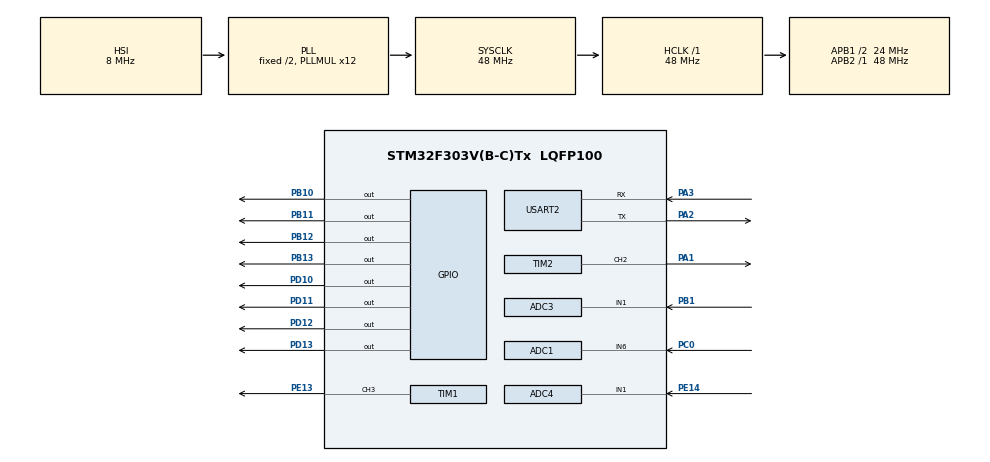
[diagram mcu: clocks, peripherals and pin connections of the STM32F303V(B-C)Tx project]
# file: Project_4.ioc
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ADC1.Channel-1\#ChannelRegularConversion=ADC_CHANNEL_6
ADC1.NbrOfConversionFlag=1
ADC1.Offset-1\#ChannelRegularConversion=0
ADC1.OffsetNumber-1\#ChannelRegularConversion=ADC_OFFSET_NONE
ADC1.Rank-1\#ChannelRegularConversion=1
ADC1.SamplingTime-1\#ChannelRegularConversion=ADC_SAMPLETIME_601CYCLES_5
ADC1.SamplingTimeOPAMP-1\#ChannelRegularConversion=ADC_SAMPLETIME_19CYCLES_5
ADC1.master=1
ADC3.Channel-0\#ChannelRegularConversion=ADC_CHANNEL_1
ADC3.NbrOfConversionFlag=1
ADC3.Offset-0\#ChannelRegularConversion=0
ADC3.OffsetNumber-0\#ChannelRegularConversion=ADC_OFFSET_NONE
ADC3.Rank-0\#ChannelRegularConversion=1
ADC3.SamplingTime-0\#ChannelRegularConversion=ADC_SAMPLETIME_601CYCLES_5
ADC3.SamplingTimeOPAMP-0\#ChannelRegularConversion=ADC_SAMPLETIME_19CYCLES_5
ADC3.master=1
ADC4.Channel-1\#ChannelRegularConversion=ADC_CHANNEL_1
ADC4.NbrOfConversionFlag=1
ADC4.Offset-1\#ChannelRegularConversion=0
ADC4.OffsetNumber-1\#ChannelRegularConversion=ADC_OFFSET_NONE
ADC4.Rank-1\#ChannelRegularConversion=1
ADC4.SamplingTime-1\#ChannelRegularConversion=ADC_SAMPLETIME_601CYCLES_5
Mcu.Family=STM32F3
Mcu.Name=STM32F303V(B-C)Tx
Mcu.Package=LQFP100
NVIC.ADC1_2_IRQn=true\:0\:0\:true\:false\:true\:true\:true
NVIC.ADC3_IRQn=true\:0\:0\:true\:false\:true\:true\:true
NVIC.ADC4_IRQn=true\:0\:0\:true\:false\:true\:true\:true
NVIC.PriorityGroup=NVIC_PRIORITYGROUP_4
NVIC.TIM3_IRQn=true\:0\:0\:true\:false\:true\:true\:true
NVIC.TIM4_IRQn=true\:0\:0\:true\:false\:true\:true\:true
NVIC.TIM6_DAC_IRQn=true\:0\:0\:true\:false\:true\:true\:true
NVIC.USART2_IRQn=true\:0\:0\:true\:false\:true\:true\:true
PA1.Signal=S_TIM2_CH2
PA2.Mode=Asynchronous
PA2.Signal=USART2_TX
PA3.Mode=Asynchronous
PA3.Signal=USART2_RX
PB1.Mode=IN1-Single-Ended
PB1.Signal=ADC3_IN1
PB10.Signal=GPIO_Output
PB11.Signal=GPIO_Output
PB12.Signal=GPIO_Output
PB13.Signal=GPIO_Output
PC0.Signal=ADCx_IN6
PD10.Signal=GPIO_Output
PD11.Signal=GPIO_Output
PD12.Signal=GPIO_Output
PD13.Signal=GPIO_Output
PE13.Signal=S_TIM1_CH3
PE14.Mode=IN1-Single-Ended
PE14.Signal=ADC4_IN1
ProjectManager.HeapSize=0x200
ProjectManager.StackSize=0x400
ProjectManager.TargetToolchain=STM32CubeIDE
RCC.AHBFreq_Value=48000000
RCC.APB1CLKDivider=RCC_HCLK_DIV2
RCC.APB1Freq_Value=24000000
RCC.APB1TimFreq_Value=48000000
RCC.APB2Freq_Value=48000000
RCC.APB2TimFreq_Value=48000000
RCC.CortexFreq_Value=48000000
RCC.HCLKFreq_Value=48000000
RCC.HSE_VALUE=8000000
RCC.HSI_VALUE=8000000
RCC.LSE_VALUE=32768
RCC.PLLMUL=RCC_PLL_MUL12
RCC.SYSCLKFreq_VALUE=48000000
RCC.SYSCLKSourceVirtual=RCC_SYSCLKSOURCE_PLLCLK
RCC.USBFreq_Value=48000000
SH.ADCx_IN6.0=ADC1_IN6,IN6-Single-Ended
SH.S_TIM1_CH3.0=TIM1_CH3,PWM Generation3 CH3
SH.S_TIM2_CH2.0=TIM2_CH2,PWM Generation2 CH2
TIM1.Channel-PWM\ Generation3\ CH3=TIM_CHANNEL_3
TIM1.Period=9
TIM1.Prescaler=9
TIM2.Channel-PWM\ Generation2\ CH2=TIM_CHANNEL_2
TIM3.Period=9999
TIM3.Prescaler=47
TIM4.Period=999
TIM4.Prescaler=191
TIM6.Period=9999
TIM6.Prescaler=239
USART2.VirtualMode-Asynchronous=VM_ASYNC
VP_TIM1_VS_ClockSourceINT.Mode=Internal
VP_TIM2_VS_ClockSourceINT.Mode=Internal
VP_TIM3_VS_ClockSourceINT.Mode=Internal
VP_TIM4_VS_ClockSourceINT.Mode=Internal
VP_TIM6_VS_ClockSourceINT.Mode=Enable_Timer
board=custom

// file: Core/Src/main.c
/* USER CODE BEGIN Header */
/**
  ******************************************************************************
  * @file           : main.c
  * @brief          : Main program body
  ******************************************************************************
  * @attention
  *
  * <h2><center>&copy; Copyright (c) 2022 STMicroelectronics.
  * All rights reserved.</center></h2>
  *
  * This software component is licensed by ST under BSD 3-Clause license,
  * the "License"; You may not use this file except in compliance with the
  * License. You may obtain a copy of the License at:
  *                        opensource.org/licenses/BSD-3-Clause
  *
  ******************************************************************************
  */
/* USER CODE END Header */
#include "main.h"

ADC_HandleTypeDef hadc1;
ADC_HandleTypeDef hadc3;
ADC_HandleTypeDef hadc4;

TIM_HandleTypeDef htim1;
TIM_HandleTypeDef htim2;
TIM_HandleTypeDef htim3;
TIM_HandleTypeDef htim4;
TIM_HandleTypeDef htim6;

UART_HandleTypeDef huart2;

void SystemClock_Config(void);

static void MX_GPIO_Init(void);

static void MX_USART2_UART_Init(void);

static void MX_ADC4_Init(void);

static void MX_ADC1_Init(void);

static void MX_TIM1_Init(void);

static void MX_TIM2_Init(void);

static void MX_TIM3_Init(void);

static void MX_ADC3_Init(void);

static void MX_TIM4_Init(void);

static void MX_TIM6_Init(void);

/* USER CODE BEGIN 0 */
TIM_HandleTypeDef *pwm_timer = &htim2;
uint32_t pwm_channel = TIM_CHANNEL_2;

void PWM_Start() {
    HAL_TIM_PWM_Start(pwm_timer, pwm_channel);
}
/* USER CODE END 0 */

int main(void) {

    /* MCU Configuration--------------------------------------------------------*/

    /* Reset of all peripherals, Initializes the Flash interface and the Systick. */
    HAL_Init();

    /* Configure the system clock */
    SystemClock_Config();

    /* Initialize all configured peripherals */
    MX_GPIO_Init();
    MX_USART2_UART_Init();
    MX_ADC4_Init();
    MX_ADC1_Init();
    MX_TIM1_Init();
    MX_TIM2_Init();
    MX_TIM3_Init();
    MX_ADC3_Init();
    MX_TIM4_Init();
    MX_TIM6_Init();
    /* USER CODE BEGIN 2 */
    HAL_ADC_Start_IT(&hadc1);
    HAL_ADC_Start_IT(&hadc3);
    HAL_ADC_Start_IT(&hadc4);

    HAL_TIM_PWM_Start(&htim1, TIM_CHANNEL_3);

    PWM_Start();

    HAL_TIM_Base_Start_IT(&htim3);
    HAL_TIM_Base_Start_IT(&htim4);
    HAL_TIM_Base_Start_IT(&htim6);
    /* USER CODE END 2 */

    /* Infinite loop */
    while (1) {

    }
}

void SystemClock_Config(void) {
    RCC_OscInitTypeDef RCC_OscInitStruct = {0};
    RCC_ClkInitTypeDef RCC_ClkInitStruct = {0};
    RCC_PeriphCLKInitTypeDef PeriphClkInit = {0};

    /** Initializes the RCC Oscillators according to the specified parameters
    * in the RCC_OscInitTypeDef structure.
    */
    RCC_OscInitStruct.OscillatorType = RCC_OSCILLATORTYPE_HSI;
    RCC_OscInitStruct.HSIState = RCC_HSI_ON;
    RCC_OscInitStruct.HSICalibrationValue = RCC_HSICALIBRATION_DEFAULT;
    RCC_OscInitStruct.PLL.PLLState = RCC_PLL_ON;
    RCC_OscInitStruct.PLL.PLLSource = RCC_PLLSOURCE_HSI;
    RCC_OscInitStruct.PLL.PLLMUL = RCC_PLL_MUL12;
    if (HAL_RCC_OscConfig(&RCC_OscInitStruct) != HAL_OK) {
        Error_Handler();
    }
    /** Initializes the CPU, AHB and APB buses clocks
    */
    RCC_ClkInitStruct.ClockType = RCC_CLOCKTYPE_HCLK | RCC_CLOCKTYPE_SYSCLK
                                  | RCC_CLOCKTYPE_PCLK1 | RCC_CLOCKTYPE_PCLK2;
    RCC_ClkInitStruct.SYSCLKSource = RCC_SYSCLKSOURCE_PLLCLK;
    RCC_ClkInitStruct.AHBCLKDivider = RCC_SYSCLK_DIV1;
    RCC_ClkInitStruct.APB1CLKDivider = RCC_HCLK_DIV2;
    RCC_ClkInitStruct.APB2CLKDivider = RCC_HCLK_DIV1;

    if (HAL_RCC_ClockConfig(&RCC_ClkInitStruct, FLASH_LATENCY_1) != HAL_OK) {
        Error_Handler();
    }
    PeriphClkInit.PeriphClockSelection = RCC_PERIPHCLK_USART2 | RCC_PERIPHCLK_TIM1
                                         | RCC_PERIPHCLK_ADC12 | RCC_PERIPHCLK_ADC34;
    PeriphClkInit.Usart2ClockSelection = RCC_USART2CLKSOURCE_PCLK1;
    PeriphClkInit.Adc12ClockSelection = RCC_ADC12PLLCLK_DIV1;
    PeriphClkInit.Adc34ClockSelection = RCC_ADC34PLLCLK_DIV1;
    PeriphClkInit.Tim1ClockSelection = RCC_TIM1CLK_HCLK;
    if (HAL_RCCEx_PeriphCLKConfig(&PeriphClkInit) != HAL_OK) {
        Error_Handler();
    }
}

static void MX_ADC1_Init(void) {

    ADC_MultiModeTypeDef multimode = {0};
    ADC_ChannelConfTypeDef sConfig = {0};

    /** Common config
    */
    hadc1.Instance = ADC1;
    hadc1.Init.ClockPrescaler = ADC_CLOCK_ASYNC_DIV1;
    hadc1.Init.Resolution = ADC_RESOLUTION_12B;
    hadc1.Init.ScanConvMode = ADC_SCAN_DISABLE;
    hadc1.Init.ContinuousConvMode = DISABLE;
    hadc1.Init.DiscontinuousConvMode = DISABLE;
    hadc1.Init.ExternalTrigConvEdge = ADC_EXTERNALTRIGCONVEDGE_NONE;
    hadc1.Init.ExternalTrigConv = ADC_SOFTWARE_START;
    hadc1.Init.DataAlign = ADC_DATAALIGN_RIGHT;
    hadc1.Init.NbrOfConversion = 1;
    hadc1.Init.DMAContinuousRequests = DISABLE;
    hadc1.Init.EOCSelection = ADC_EOC_SINGLE_CONV;
    hadc1.Init.LowPowerAutoWait = DISABLE;
    hadc1.Init.Overrun = ADC_OVR_DATA_OVERWRITTEN;
    if (HAL_ADC_Init(&hadc1) != HAL_OK) {
        Error_Handler();
    }
    /** Configure the ADC multi-mode
    */
    multimode.Mode = ADC_MODE_INDEPENDENT;
    if (HAL_ADCEx_MultiModeConfigChannel(&hadc1, &multimode) != HAL_OK) {
        Error_Handler();
    }
    /** Configure Regular Channel
    */
    sConfig.Channel = ADC_CHANNEL_6;
    sConfig.Rank = ADC_REGULAR_RANK_1;
    sConfig.SingleDiff = ADC_SINGLE_ENDED;
    sConfig.SamplingTime = ADC_SAMPLETIME_601CYCLES_5;
    sConfig.OffsetNumber = ADC_OFFSET_NONE;
    sConfig.Offset = 0;
    if (HAL_ADC_ConfigChannel(&hadc1, &sConfig) != HAL_OK) {
        Error_Handler();
    }

}

static void MX_ADC3_Init(void) {

    ADC_MultiModeTypeDef multimode = {0};
    ADC_ChannelConfTypeDef sConfig = {0};

    /** Common config
    */
    hadc3.Instance = ADC3;
    hadc3.Init.ClockPrescaler = ADC_CLOCK_ASYNC_DIV1;
    hadc3.Init.Resolution = ADC_RESOLUTION_12B;
    hadc3.Init.ScanConvMode = ADC_SCAN_DISABLE;
    hadc3.Init.ContinuousConvMode = DISABLE;
    hadc3.Init.DiscontinuousConvMode = DISABLE;
    hadc3.Init.ExternalTrigConvEdge = ADC_EXTERNALTRIGCONVEDGE_NONE;
    hadc3.Init.ExternalTrigConv = ADC_SOFTWARE_START;
    hadc3.Init.DataAlign = ADC_DATAALIGN_RIGHT;
    hadc3.Init.NbrOfConversion = 1;
    hadc3.Init.DMAContinuousRequests = DISABLE;
    hadc3.Init.EOCSelection = ADC_EOC_SINGLE_CONV;
    hadc3.Init.LowPowerAutoWait = DISABLE;
    hadc3.Init.Overrun = ADC_OVR_DATA_OVERWRITTEN;
    if (HAL_ADC_Init(&hadc3) != HAL_OK) {
        Error_Handler();
    }
    /** Configure the ADC multi-mode
    */
    multimode.Mode = ADC_MODE_INDEPENDENT;
    if (HAL_ADCEx_MultiModeConfigChannel(&hadc3, &multimode) != HAL_OK) {
        Error_Handler();
    }
    /** Configure Regular Channel
    */
    sConfig.Channel = ADC_CHANNEL_1;
    sConfig.Rank = ADC_REGULAR_RANK_1;
    sConfig.SingleDiff = ADC_SINGLE_ENDED;
    sConfig.SamplingTime = ADC_SAMPLETIME_601CYCLES_5;
    sConfig.OffsetNumber = ADC_OFFSET_NONE;
    sConfig.Offset = 0;
    if (HAL_ADC_ConfigChannel(&hadc3, &sConfig) != HAL_OK) {
        Error_Handler();
    }

}

static void MX_ADC4_Init(void) {

    ADC_ChannelConfTypeDef sConfig = {0};

    /** Common config
    */
    hadc4.Instance = ADC4;
    hadc4.Init.ClockPrescaler = ADC_CLOCK_ASYNC_DIV1;
    hadc4.Init.Resolution = ADC_RESOLUTION_12B;
    hadc4.Init.ScanConvMode = ADC_SCAN_DISABLE;
    hadc4.Init.ContinuousConvMode = DISABLE;
    hadc4.Init.DiscontinuousConvMode = DISABLE;
    hadc4.Init.ExternalTrigConvEdge = ADC_EXTERNALTRIGCONVEDGE_NONE;
    hadc4.Init.ExternalTrigConv = ADC_SOFTWARE_START;
    hadc4.Init.DataAlign = ADC_DATAALIGN_RIGHT;
    hadc4.Init.NbrOfConversion = 1;
    hadc4.Init.DMAContinuousRequests = DISABLE;
    hadc4.Init.EOCSelection = ADC_EOC_SINGLE_CONV;
    hadc4.Init.LowPowerAutoWait = DISABLE;
    hadc4.Init.Overrun = ADC_OVR_DATA_OVERWRITTEN;
    if (HAL_ADC_Init(&hadc4) != HAL_OK) {
        Error_Handler();
    }
    /** Configure Regular Channel
    */
    sConfig.Channel = ADC_CHANNEL_1;
    sConfig.Rank = ADC_REGULAR_RANK_1;
    sConfig.SingleDiff = ADC_SINGLE_ENDED;
    sConfig.SamplingTime = ADC_SAMPLETIME_601CYCLES_5;
    sConfig.OffsetNumber = ADC_OFFSET_NONE;
    sConfig.Offset = 0;
    if (HAL_ADC_ConfigChannel(&hadc4, &sConfig) != HAL_OK) {
        Error_Handler();
    }

}

static void MX_TIM1_Init(void) {

    TIM_ClockConfigTypeDef sClockSourceConfig = {0};
    TIM_MasterConfigTypeDef sMasterConfig = {0};
    TIM_OC_InitTypeDef sConfigOC = {0};
    TIM_BreakDeadTimeConfigTypeDef sBreakDeadTimeConfig = {0};

    htim1.Instance = TIM1;
    htim1.Init.Prescaler = 9;
    htim1.Init.CounterMode = TIM_COUNTERMODE_UP;
    htim1.Init.Period = 9;
    htim1.Init.ClockDivision = TIM_CLOCKDIVISION_DIV1;
    htim1.Init.RepetitionCounter = 0;
    htim1.Init.AutoReloadPreload = TIM_AUTORELOAD_PRELOAD_DISABLE;
    if (HAL_TIM_Base_Init(&htim1) != HAL_OK) {
        Error_Handler();
    }
    sClockSourceConfig.ClockSource = TIM_CLOCKSOURCE_INTERNAL;
    if (HAL_TIM_ConfigClockSource(&htim1, &sClockSourceConfig) != HAL_OK) {
        Error_Handler();
    }
    if (HAL_TIM_PWM_Init(&htim1) != HAL_OK) {
        Error_Handler();
    }
    sMasterConfig.MasterOutputTrigger = TIM_TRGO_RESET;
    sMasterConfig.MasterOutputTrigger2 = TIM_TRGO2_RESET;
    sMasterConfig.MasterSlaveMode = TIM_MASTERSLAVEMODE_DISABLE;
    if (HAL_TIMEx_MasterConfigSynchronization(&htim1, &sMasterConfig) != HAL_OK) {
        Error_Handler();
    }
    sConfigOC.OCMode = TIM_OCMODE_PWM1;
    sConfigOC.Pulse = 0;
    sConfigOC.OCPolarity = TIM_OCPOLARITY_HIGH;
    sConfigOC.OCNPolarity = TIM_OCNPOLARITY_HIGH;
    sConfigOC.OCFastMode = TIM_OCFAST_DISABLE;
    sConfigOC.OCIdleState = TIM_OCIDLESTATE_RESET;
    sConfigOC.OCNIdleState = TIM_OCNIDLESTATE_RESET;
    if (HAL_TIM_PWM_ConfigChannel(&htim1, &sConfigOC, TIM_CHANNEL_3) != HAL_OK) {
        Error_Handler();
    }
    sBreakDeadTimeConfig.OffStateRunMode = TIM_OSSR_DISABLE;
    sBreakDeadTimeConfig.OffStateIDLEMode = TIM_OSSI_DISABLE;
    sBreakDeadTimeConfig.LockLevel = TIM_LOCKLEVEL_OFF;
    sBreakDeadTimeConfig.DeadTime = 0;
    sBreakDeadTimeConfig.BreakState = TIM_BREAK_DISABLE;
    sBreakDeadTimeConfig.BreakPolarity = TIM_BREAKPOLARITY_HIGH;
    sBreakDeadTimeConfig.BreakFilter = 0;
    sBreakDeadTimeConfig.Break2State = TIM_BREAK2_DISABLE;
    sBreakDeadTimeConfig.Break2Polarity = TIM_BREAK2POLARITY_HIGH;
    sBreakDeadTimeConfig.Break2Filter = 0;
    sBreakDeadTimeConfig.AutomaticOutput = TIM_AUTOMATICOUTPUT_DISABLE;
    if (HAL_TIMEx_ConfigBreakDeadTime(&htim1, &sBreakDeadTimeConfig) != HAL_OK) {
        Error_Handler();
    }
    HAL_TIM_MspPostInit(&htim1);

}

static void MX_TIM2_Init(void) {

    TIM_ClockConfigTypeDef sClockSourceConfig = {0};
    TIM_MasterConfigTypeDef sMasterConfig = {0};
    TIM_OC_InitTypeDef sConfigOC = {0};

    htim2.Instance = TIM2;
    htim2.Init.Prescaler = 0;
    htim2.Init.CounterMode = TIM_COUNTERMODE_UP;
    htim2.Init.Period = 4294967295;
    htim2.Init.ClockDivision = TIM_CLOCKDIVISION_DIV1;
    htim2.Init.AutoReloadPreload = TIM_AUTORELOAD_PRELOAD_DISABLE;
    if (HAL_TIM_Base_Init(&htim2) != HAL_OK) {
        Error_Handler();
    }
    sClockSourceConfig.ClockSource = TIM_CLOCKSOURCE_INTERNAL;
    if (HAL_TIM_ConfigClockSource(&htim2, &sClockSourceConfig) != HAL_OK) {
        Error_Handler();
    }
    if (HAL_TIM_PWM_Init(&htim2) != HAL_OK) {
        Error_Handler();
    }
    sMasterConfig.MasterOutputTrigger = TIM_TRGO_RESET;
    sMasterConfig.MasterSlaveMode = TIM_MASTERSLAVEMODE_DISABLE;
    if (HAL_TIMEx_MasterConfigSynchronization(&htim2, &sMasterConfig) != HAL_OK) {
        Error_Handler();
    }
    sConfigOC.OCMode = TIM_OCMODE_PWM1;
    sConfigOC.Pulse = 0;
    sConfigOC.OCPolarity = TIM_OCPOLARITY_HIGH;
    sConfigOC.OCFastMode = TIM_OCFAST_DISABLE;
    if (HAL_TIM_PWM_ConfigChannel(&htim2, &sConfigOC, TIM_CHANNEL_2) != HAL_OK) {
        Error_Handler();
    }
    HAL_TIM_MspPostInit(&htim2);

}

static void MX_TIM3_Init(void) {

    TIM_ClockConfigTypeDef sClockSourceConfig = {0};
    TIM_MasterConfigTypeDef sMasterConfig = {0};

    htim3.Instance = TIM3;
    htim3.Init.Prescaler = 47;
    htim3.Init.CounterMode = TIM_COUNTERMODE_UP;
    htim3.Init.Period = 9999;
    htim3.Init.ClockDivision = TIM_CLOCKDIVISION_DIV1;
    htim3.Init.AutoReloadPreload = TIM_AUTORELOAD_PRELOAD_DISABLE;
    if (HAL_TIM_Base_Init(&htim3) != HAL_OK) {
        Error_Handler();
    }
    sClockSourceConfig.ClockSource = TIM_CLOCKSOURCE_INTERNAL;
    if (HAL_TIM_ConfigClockSource(&htim3, &sClockSourceConfig) != HAL_OK) {
        Error_Handler();
    }
    sMasterConfig.MasterOutputTrigger = TIM_TRGO_RESET;
    sMasterConfig.MasterSlaveMode = TIM_MASTERSLAVEMODE_DISABLE;
    if (HAL_TIMEx_MasterConfigSynchronization(&htim3, &sMasterConfig) != HAL_OK) {
        Error_Handler();
    }

}

static void MX_TIM4_Init(void) {

    TIM_ClockConfigTypeDef sClockSourceConfig = {0};
    TIM_MasterConfigTypeDef sMasterConfig = {0};

    htim4.Instance = TIM4;
    htim4.Init.Prescaler = 191;
    htim4.Init.CounterMode = TIM_COUNTERMODE_UP;
    htim4.Init.Period = 999;
    htim4.Init.ClockDivision = TIM_CLOCKDIVISION_DIV1;
    htim4.Init.AutoReloadPreload = TIM_AUTORELOAD_PRELOAD_DISABLE;
    if (HAL_TIM_Base_Init(&htim4) != HAL_OK) {
        Error_Handler();
    }
    sClockSourceConfig.ClockSource = TIM_CLOCKSOURCE_INTERNAL;
    if (HAL_TIM_ConfigClockSource(&htim4, &sClockSourceConfig) != HAL_OK) {
        Error_Handler();
    }
    sMasterConfig.MasterOutputTrigger = TIM_TRGO_RESET;
    sMasterConfig.MasterSlaveMode = TIM_MASTERSLAVEMODE_DISABLE;
    if (HAL_TIMEx_MasterConfigSynchronization(&htim4, &sMasterConfig) != HAL_OK) {
        Error_Handler();
    }

}

static void MX_TIM6_Init(void) {

    TIM_MasterConfigTypeDef sMasterConfig = {0};

    htim6.Instance = TIM6;
    htim6.Init.Prescaler = 239;
    htim6.Init.CounterMode = TIM_COUNTERMODE_UP;
    htim6.Init.Period = 9999;
    htim6.Init.AutoReloadPreload = TIM_AUTORELOAD_PRELOAD_DISABLE;
    if (HAL_TIM_Base_Init(&htim6) != HAL_OK) {
        Error_Handler();
    }
    sMasterConfig.MasterOutputTrigger = TIM_TRGO_RESET;
    sMasterConfig.MasterSlaveMode = TIM_MASTERSLAVEMODE_DISABLE;
    if (HAL_TIMEx_MasterConfigSynchronization(&htim6, &sMasterConfig) != HAL_OK) {
        Error_Handler();
    }

}

static void MX_USART2_UART_Init(void) {

    huart2.Instance = USART2;
    huart2.Init.BaudRate = 38400;
    huart2.Init.WordLength = UART_WORDLENGTH_8B;
    huart2.Init.StopBits = UART_STOPBITS_1;
    huart2.Init.Parity = UART_PARITY_NONE;
    huart2.Init.Mode = UART_MODE_TX_RX;
    huart2.Init.HwFlowCtl = UART_HWCONTROL_NONE;
    huart2.Init.OverSampling = UART_OVERSAMPLING_16;
    huart2.Init.OneBitSampling = UART_ONE_BIT_SAMPLE_DISABLE;
    huart2.AdvancedInit.AdvFeatureInit = UART_ADVFEATURE_NO_INIT;
    if (HAL_UART_Init(&huart2) != HAL_OK) {
        Error_Handler();
    }

}

static void MX_GPIO_Init(void) {
    GPIO_InitTypeDef GPIO_InitStruct = {0};

    /* GPIO Ports Clock Enable */
    __HAL_RCC_GPIOC_CLK_ENABLE();
    __HAL_RCC_GPIOA_CLK_ENABLE();
    __HAL_RCC_GPIOB_CLK_ENABLE();
    __HAL_RCC_GPIOE_CLK_ENABLE();
    __HAL_RCC_GPIOD_CLK_ENABLE();

    /*Configure GPIO pin Output Level */
    HAL_GPIO_WritePin(GPIOB, GPIO_PIN_10 | GPIO_PIN_11 | GPIO_PIN_12 | GPIO_PIN_13, GPIO_PIN_RESET);

    /*Configure GPIO pin Output Level */
    HAL_GPIO_WritePin(GPIOD, GPIO_PIN_10 | GPIO_PIN_11 | GPIO_PIN_12 | GPIO_PIN_13, GPIO_PIN_RESET);

    /*Configure GPIO pins : PB10 PB11 PB12 PB13 */
    GPIO_InitStruct.Pin = GPIO_PIN_10 | GPIO_PIN_11 | GPIO_PIN_12 | GPIO_PIN_13;
    GPIO_InitStruct.Mode = GPIO_MODE_OUTPUT_PP;
    GPIO_InitStruct.Pull = GPIO_NOPULL;
    GPIO_InitStruct.Speed = GPIO_SPEED_FREQ_LOW;
    HAL_GPIO_Init(GPIOB, &GPIO_InitStruct);

    /*Configure GPIO pins : PD10 PD11 PD12 PD13 */
    GPIO_InitStruct.Pin = GPIO_PIN_10 | GPIO_PIN_11 | GPIO_PIN_12 | GPIO_PIN_13;
    GPIO_InitStruct.Mode = GPIO_MODE_OUTPUT_PP;
    GPIO_InitStruct.Pull = GPIO_NOPULL;
    GPIO_InitStruct.Speed = GPIO_SPEED_FREQ_LOW;
    HAL_GPIO_Init(GPIOD, &GPIO_InitStruct);

}

void Error_Handler(void) {
    __disable_irq();
    while (1) {
    }
}

/************************ (C) COPYRIGHT STMicroelectronics *****END OF FILE****/
